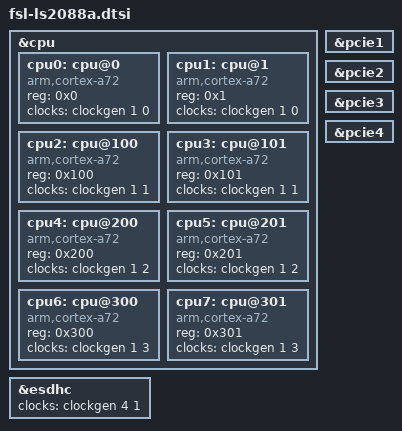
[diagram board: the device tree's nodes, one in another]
/*
 * Device Tree file for Freescale LS2088A RDB Board.
 *
 * Copyright (C) 2016-17, Freescale Semiconductor
 *
 * Abhimanyu Saini <abhimanyu.saini@nxp.com>
 *
 * This file is dual-licensed: you can use it either under the terms
 * of the GPLv2 or the X11 license, at your option. Note that this dual
 * licensing only applies to this file, and not this project as a
 * whole.
 *
 *  a) This library is free software; you can redistribute it and/or
 *     modify it under the terms of the GNU General Public License as
 *     published by the Free Software Foundation; either version 2 of the
 *     License, or (at your option) any later version.
 *
 *     This library is distributed in the hope that it will be useful,
 *     but WITHOUT ANY WARRANTY; without even the implied warranty of
 *     MERCHANTABILITY or FITNESS FOR A PARTICULAR PURPOSE.  See the
 *     GNU General Public License for more details.
 *
 * Or, alternatively,
 *
 *  b) Permission is hereby granted, free of charge, to any person
 *     obtaining a copy of this software and associated documentation
 *     files (the "Software"), to deal in the Software without
 *     restriction, including without limitation the rights to use,
 *     copy, modify, merge, publish, distribute, sublicense, and/or
 *     sell copies of the Software, and to permit persons to whom the
 *     Software is furnished to do so, subject to the following
 *     conditions:
 *
 *     The above copyright notice and this permission notice shall be
 *     included in all copies or substantial portions of the Software.
 *
 *     THE SOFTWARE IS PROVIDED "AS IS", WITHOUT WARRANTY OF ANY KIND,
 *     EXPRESS OR IMPLIED, INCLUDING BUT NOT LIMITED TO THE WARRANTIES
 *     OF MERCHANTABILITY, FITNESS FOR A PARTICULAR PURPOSE AND
 *     NONINFRINGEMENT. IN NO EVENT SHALL THE AUTHORS OR COPYRIGHT
 *     HOLDERS BE LIABLE FOR ANY CLAIM, DAMAGES OR OTHER LIABILITY,
 *     WHETHER IN AN ACTION OF CONTRACT, TORT OR OTHERWISE, ARISING
 *     FROM, OUT OF OR IN CONNECTION WITH THE SOFTWARE OR THE USE OR
 *     OTHER DEALINGS IN THE SOFTWARE.
 */

/memreserve/ 0x80000000 0x00010000;

#include "fsl-ls208xa.dtsi"


&cpu {
	cpu0: cpu@0 {
		device_type = "cpu";
		compatible = "arm,cortex-a72";
		reg = <0x0>;
		clocks = <&clockgen 1 0>;
		#cooling-cells = <2>;
	};

	cpu1: cpu@1 {
		device_type = "cpu";
		compatible = "arm,cortex-a72";
		reg = <0x1>;
		clocks = <&clockgen 1 0>;
	};

	cpu2: cpu@100 {
		device_type = "cpu";
		compatible = "arm,cortex-a72";
		reg = <0x100>;
		clocks = <&clockgen 1 1>;
		#cooling-cells = <2>;
	};

	cpu3: cpu@101 {
		device_type = "cpu";
		compatible = "arm,cortex-a72";
		reg = <0x101>;
		clocks = <&clockgen 1 1>;
	};

	cpu4: cpu@200 {
		device_type = "cpu";
		compatible = "arm,cortex-a72";
		reg = <0x200>;
		clocks = <&clockgen 1 2>;
		#cooling-cells = <2>;
	};

	cpu5: cpu@201 {
		device_type = "cpu";
		compatible = "arm,cortex-a72";
		reg = <0x201>;
		clocks = <&clockgen 1 2>;
	};

	cpu6: cpu@300 {
		device_type = "cpu";
		compatible = "arm,cortex-a72";
		reg = <0x300>;
		clocks = <&clockgen 1 3>;
		#cooling-cells = <2>;
	};

	cpu7: cpu@301 {
		device_type = "cpu";
		compatible = "arm,cortex-a72";
		reg = <0x301>;
		clocks = <&clockgen 1 3>;
	};
};

&pcie1 {
	ranges = <0x81000000 0x0 0x00000000 0x20 0x00010000 0x0 0x00010000   /* downstream I/O */
		  0x82000000 0x0 0x40000000 0x20 0x40000000 0x0 0x40000000>; /* non-prefetchable memory */
};

&pcie2 {
	ranges = <0x81000000 0x0 0x00000000 0x28 0x00010000 0x0 0x00010000   /* downstream I/O */
		  0x82000000 0x0 0x40000000 0x28 0x40000000 0x0 0x40000000>; /* non-prefetchable memory */
};

&pcie3 {
	ranges = <0x81000000 0x0 0x00000000 0x30 0x00010000 0x0 0x00010000   /* downstream I/O */
		  0x82000000 0x0 0x40000000 0x30 0x40000000 0x0 0x40000000>; /* non-prefetchable memory */
};
&pcie4 {
	ranges = <0x81000000 0x0 0x00000000 0x38 0x00010000 0x0 0x00010000   /* downstream I/O */
		  0x82000000 0x0 0x40000000 0x38 0x40000000 0x0 0x40000000>; /* non-prefetchable memory */
};

&esdhc {
	clocks = <&clockgen 4 1>;
};
